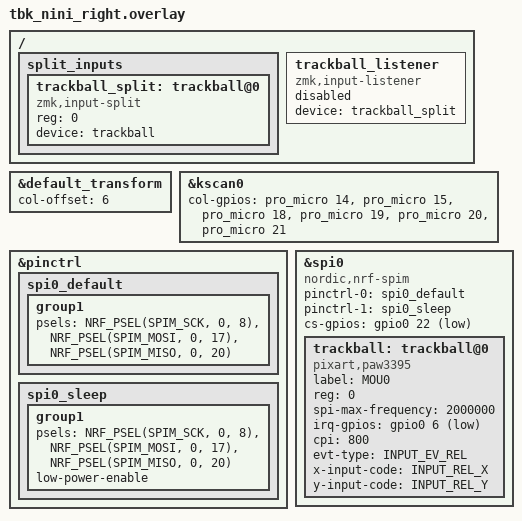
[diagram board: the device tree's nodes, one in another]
/*
 * Copyright (c) 2020 Pete Johanson
 *
 * SPDX-License-Identifier: MIT
 */

#include "tbk_nini.dtsi"


&default_transform {
    col-offset = <6>;
};

&kscan0 {
    col-gpios
        = <&pro_micro 14 GPIO_ACTIVE_HIGH>
        , <&pro_micro 15 GPIO_ACTIVE_HIGH>
        , <&pro_micro 18 GPIO_ACTIVE_HIGH>
        , <&pro_micro 19 GPIO_ACTIVE_HIGH>
        , <&pro_micro 20 GPIO_ACTIVE_HIGH>
        , <&pro_micro 21 GPIO_ACTIVE_HIGH>
        ;
};

&pinctrl {
    spi0_default: spi0_default {
        group1 {
            psels = <NRF_PSEL(SPIM_SCK, 0, 8)>,
                <NRF_PSEL(SPIM_MOSI, 0, 17)>,
                <NRF_PSEL(SPIM_MISO, 0, 20)>;
        };
    };

    spi0_sleep: spi0_sleep {
        group1 {
            psels = <NRF_PSEL(SPIM_SCK, 0, 8)>,
                <NRF_PSEL(SPIM_MOSI, 0, 17)>,
                <NRF_PSEL(SPIM_MISO, 0, 20)>;
            low-power-enable;
        };
    };
};

#include <zephyr/dt-bindings/input/input-event-codes.h>

&spi0 {
  status = "okay";
  compatible = "nordic,nrf-spim";
  pinctrl-0 = <&spi0_default>;
  pinctrl-1 = <&spi0_sleep>;
  pinctrl-names = "default", "sleep";
  cs-gpios = <&gpio0 22 GPIO_ACTIVE_LOW>;

  trackball: trackball@0 {
    compatible = "pixart,paw3395";
    status = "okay";
    label = "MOU0";
    reg = <0>;
    spi-max-frequency = <2000000>;

    // paw3395 driver parameters
    irq-gpios = <&gpio0 6 (GPIO_ACTIVE_LOW | GPIO_PULL_UP)>;
    cpi = <800>;
    // swap-xy; /* optional */
    // invert-x; /* optional */
    // invert-y; /* optional */
    evt-type = <INPUT_EV_REL>;
    x-input-code = <INPUT_REL_X>;
    y-input-code = <INPUT_REL_Y>;
  };
};

/ {
    split_inputs {
        #address-cells = <1>;
        #size-cells = <0>;

        trackball_split: trackball@0 {
            compatible = "zmk,input-split";
            reg = <0>;
            device = <&trackball>;
        };
    };

    trackball_listener: trackball_listener {
        compatible = "zmk,input-listener";
        status = "disabled";
        device = <&trackball_split>;
    };
};

